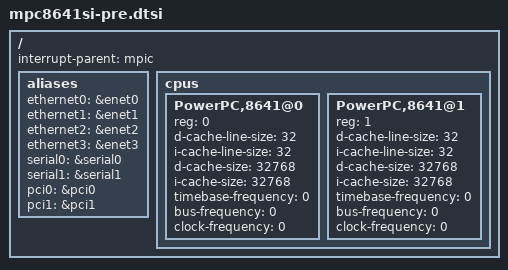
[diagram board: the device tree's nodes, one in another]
// SPDX-License-Identifier: GPL-2.0-or-later
/*
 * MPC8641 Silicon/SoC Device Tree Source (pre include)
 *
 * Copyright 2016 Elettra-Sincrotrone Trieste S.C.p.A.
 */

/dts-v1/;

/ {
	#address-cells = <1>;
	#size-cells = <1>;
	interrupt-parent = <&mpic>;

	aliases {
		ethernet0 = &enet0;
		ethernet1 = &enet1;
		ethernet2 = &enet2;
		ethernet3 = &enet3;
		serial0 = &serial0;
		serial1 = &serial1;
		pci0 = &pci0;
		pci1 = &pci1;
	};

	cpus {
		#address-cells = <1>;
		#size-cells = <0>;

		PowerPC,8641@0 {
			device_type = "cpu";
			reg = <0>;
			d-cache-line-size = <32>;
			i-cache-line-size = <32>;
			d-cache-size = <32768>;
			i-cache-size = <32768>;
			timebase-frequency = <0>;
			bus-frequency = <0>;
			clock-frequency = <0>;
		};

		PowerPC,8641@1 {
			device_type = "cpu";
			reg = <1>;
			d-cache-line-size = <32>;
			i-cache-line-size = <32>;
			d-cache-size = <32768>;
			i-cache-size = <32768>;
			timebase-frequency = <0>;
			bus-frequency = <0>;
			clock-frequency = <0>;
		};
	};
};
